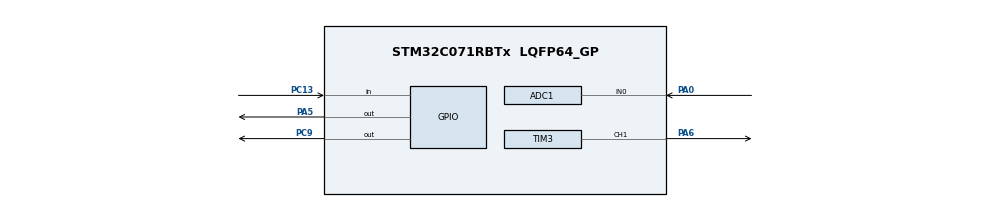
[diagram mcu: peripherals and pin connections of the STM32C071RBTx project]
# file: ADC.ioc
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ADC1.NbrOfConversionFlag=0
ADC1.SelectedChannel=ADC_CHANNEL_0
ADC1.master=1
Mcu.Family=STM32C0
Mcu.Name=STM32C071RBTx
Mcu.Package=LQFP64_GP
NUCLEO-C071RB.BUTTON=1
NUCLEO-C071RB.LD1=true
NUCLEO-C071RB.LD2=true
NUCLEO-C071RB.VCP=true
NVIC.EXTI4_15_IRQn=true\:0\:0\:false\:false\:true\:false\:true\:true
PA0.Mode=IN0
PA0.Signal=ADC1_IN0
PA2.Signal=USART2_TX
PA3.Signal=USART2_RX
PA5.Signal=GPIO_Output
PA6.Signal=S_TIM3_CH1
PC13.Signal=GPIO_Input
PC9.Signal=GPIO_Output
ProjectManager.HeapSize=0x200
ProjectManager.StackSize=0x400
ProjectManager.TargetToolchain=STM32CubeIDE
RCC.ADCFreq_Value=12000000
RCC.AHBFreq_Value=12000000
RCC.CortexFreq_Value=12000000
RCC.EXTERNAL_CLOCK_VALUE=12288000
RCC.HCLKFreq_Value=12000000
RCC.HSE_VALUE=8000000
RCC.HSI48_VALUE=48000000
RCC.HSI_VALUE=48000000
RCC.LSE_VALUE=32768
RCC.SYSCLKFreq_VALUE=12000000
SH.S_TIM3_CH1.0=TIM3_CH1,PWM Generation1 CH1
TIM3.Channel-PWM\ Generation1\ CH1=TIM_CHANNEL_1
TIM3.Period=999
TIM3.Prescaler=11
VP_NUCLEO-C071RB_VS_BSP_COMMON.Mode=COMMON
VP_TIM3_VS_ClockSourceINT.Mode=Internal
board=NUCLEO-C071RB

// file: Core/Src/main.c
/* USER CODE BEGIN Header */
/**
  ******************************************************************************
  * @file           : main.c
  * @brief          : Main program body
  ******************************************************************************
  * @attention
  *
  * Copyright (c) 2026 STMicroelectronics.
  * All rights reserved.
  *
  * This software is licensed under terms that can be found in the LICENSE file
  * in the root directory of this software component.
  * If no LICENSE file comes with this software, it is provided AS-IS.
  *
  ******************************************************************************
  */
/* USER CODE END Header */
#include "main.h"

/* USER CODE BEGIN Includes */
#include <stdio.h>
/* USER CODE END Includes */

COM_InitTypeDef BspCOMInit;
ADC_HandleTypeDef hadc1;

TIM_HandleTypeDef htim3;

/* USER CODE BEGIN PV */
uint32_t adc_value = 0;
uint32_t pwm_value = 0;
/* USER CODE END PV */

void SystemClock_Config(void);
static void MX_GPIO_Init(void);
static void MX_ADC1_Init(void);
static void MX_TIM3_Init(void);

int main(void)
{

  /* MCU Configuration--------------------------------------------------------*/

  /* Reset of all peripherals, Initializes the Flash interface and the Systick. */
  HAL_Init();

  /* Configure the system clock */
  SystemClock_Config();

  /* Initialize all configured peripherals */
  MX_GPIO_Init();
  MX_ADC1_Init();
  MX_TIM3_Init();

  /* Initialize leds */
  BSP_LED_Init(LED_GREEN);
  BSP_LED_Init(LED_BLUE);

  /* Initialize USER push-button, will be used to trigger an interrupt each time it's pressed.*/
  BSP_PB_Init(BUTTON_USER, BUTTON_MODE_EXTI);

  /* Initialize COM1 port (115200, 8 bits (7-bit data + 1 stop bit), no parity */
  BspCOMInit.BaudRate   = 115200;
  BspCOMInit.WordLength = COM_WORDLENGTH_8B;
  BspCOMInit.StopBits   = COM_STOPBITS_1;
  BspCOMInit.Parity     = COM_PARITY_NONE;
  BspCOMInit.HwFlowCtl  = COM_HWCONTROL_NONE;
  if (BSP_COM_Init(COM1, &BspCOMInit) != BSP_ERROR_NONE)
  {
    Error_Handler();
  }

  HAL_TIM_PWM_Start(&htim3, TIM_CHANNEL_1);
  printf("ADC potentiometer project started\r\n");

  /* Infinite loop */
  /* USER CODE BEGIN WHILE */
  while (1)
  {
	  /*
	     * Start ADC conversion
	     */
	    HAL_ADC_Start(&hadc1);

	    /*
	     * Wait for ADC conversion complete
	     */
	    if (HAL_ADC_PollForConversion(&hadc1, 10) == HAL_OK)
	    {
	        /*
	         * Read ADC value: 0 to 4095 for 12-bit ADC
	         */
	        adc_value = HAL_ADC_GetValue(&hadc1);

	        /*
	         * Convert ADC value to PWM duty.
	         * ADC range: 0 to 4095
	         * PWM range: 0 to 999
	         */
	        pwm_value = (adc_value * 999) / 4095;

	        /*
	         * Update PWM duty cycle
	         */
	        __HAL_TIM_SET_COMPARE(&htim3, TIM_CHANNEL_1, pwm_value);
	    }

	    HAL_ADC_Stop(&hadc1);

	    HAL_Delay(10);
    /* USER CODE END WHILE */

  }
}

void SystemClock_Config(void)
{
  RCC_OscInitTypeDef RCC_OscInitStruct = {0};
  RCC_ClkInitTypeDef RCC_ClkInitStruct = {0};

  __HAL_FLASH_SET_LATENCY(FLASH_LATENCY_0);

  /** Initializes the RCC Oscillators according to the specified parameters
  * in the RCC_OscInitTypeDef structure.
  */
  RCC_OscInitStruct.OscillatorType = RCC_OSCILLATORTYPE_HSI;
  RCC_OscInitStruct.HSIState = RCC_HSI_ON;
  RCC_OscInitStruct.HSIDiv = RCC_HSI_DIV4;
  RCC_OscInitStruct.HSICalibrationValue = RCC_HSICALIBRATION_DEFAULT;
  if (HAL_RCC_OscConfig(&RCC_OscInitStruct) != HAL_OK)
  {
    Error_Handler();
  }

  /** Initializes the CPU, AHB and APB buses clocks
  */
  RCC_ClkInitStruct.ClockType = RCC_CLOCKTYPE_HCLK|RCC_CLOCKTYPE_SYSCLK
                              |RCC_CLOCKTYPE_PCLK1;
  RCC_ClkInitStruct.SYSCLKSource = RCC_SYSCLKSOURCE_HSI;
  RCC_ClkInitStruct.SYSCLKDivider = RCC_SYSCLK_DIV1;
  RCC_ClkInitStruct.AHBCLKDivider = RCC_HCLK_DIV1;
  RCC_ClkInitStruct.APB1CLKDivider = RCC_APB1_DIV1;

  if (HAL_RCC_ClockConfig(&RCC_ClkInitStruct, FLASH_LATENCY_0) != HAL_OK)
  {
    Error_Handler();
  }
}

static void MX_ADC1_Init(void)
{

  ADC_ChannelConfTypeDef sConfig = {0};

  /** Configure the global features of the ADC (Clock, Resolution, Data Alignment and number of conversion)
  */
  hadc1.Instance = ADC1;
  hadc1.Init.ClockPrescaler = ADC_CLOCK_SYNC_PCLK_DIV1;
  hadc1.Init.Resolution = ADC_RESOLUTION_12B;
  hadc1.Init.DataAlign = ADC_DATAALIGN_RIGHT;
  hadc1.Init.ScanConvMode = ADC_SCAN_SEQ_FIXED;
  hadc1.Init.EOCSelection = ADC_EOC_SINGLE_CONV;
  hadc1.Init.LowPowerAutoWait = DISABLE;
  hadc1.Init.LowPowerAutoPowerOff = DISABLE;
  hadc1.Init.ContinuousConvMode = DISABLE;
  hadc1.Init.NbrOfConversion = 1;
  hadc1.Init.DiscontinuousConvMode = DISABLE;
  hadc1.Init.ExternalTrigConv = ADC_SOFTWARE_START;
  hadc1.Init.ExternalTrigConvEdge = ADC_EXTERNALTRIGCONVEDGE_NONE;
  hadc1.Init.DMAContinuousRequests = DISABLE;
  hadc1.Init.Overrun = ADC_OVR_DATA_PRESERVED;
  hadc1.Init.SamplingTimeCommon1 = ADC_SAMPLETIME_1CYCLE_5;
  hadc1.Init.OversamplingMode = DISABLE;
  hadc1.Init.TriggerFrequencyMode = ADC_TRIGGER_FREQ_HIGH;
  if (HAL_ADC_Init(&hadc1) != HAL_OK)
  {
    Error_Handler();
  }

  /** Configure Regular Channel
  */
  sConfig.Channel = ADC_CHANNEL_0;
  sConfig.Rank = ADC_RANK_CHANNEL_NUMBER;
  if (HAL_ADC_ConfigChannel(&hadc1, &sConfig) != HAL_OK)
  {
    Error_Handler();
  }

}

static void MX_TIM3_Init(void)
{

  TIM_ClockConfigTypeDef sClockSourceConfig = {0};
  TIM_MasterConfigTypeDef sMasterConfig = {0};
  TIM_OC_InitTypeDef sConfigOC = {0};

  htim3.Instance = TIM3;
  htim3.Init.Prescaler = 11;
  htim3.Init.CounterMode = TIM_COUNTERMODE_UP;
  htim3.Init.Period = 999;
  htim3.Init.ClockDivision = TIM_CLOCKDIVISION_DIV1;
  htim3.Init.AutoReloadPreload = TIM_AUTORELOAD_PRELOAD_DISABLE;
  if (HAL_TIM_Base_Init(&htim3) != HAL_OK)
  {
    Error_Handler();
  }
  sClockSourceConfig.ClockSource = TIM_CLOCKSOURCE_INTERNAL;
  if (HAL_TIM_ConfigClockSource(&htim3, &sClockSourceConfig) != HAL_OK)
  {
    Error_Handler();
  }
  if (HAL_TIM_PWM_Init(&htim3) != HAL_OK)
  {
    Error_Handler();
  }
  sMasterConfig.MasterOutputTrigger = TIM_TRGO_RESET;
  sMasterConfig.MasterSlaveMode = TIM_MASTERSLAVEMODE_DISABLE;
  if (HAL_TIMEx_MasterConfigSynchronization(&htim3, &sMasterConfig) != HAL_OK)
  {
    Error_Handler();
  }
  sConfigOC.OCMode = TIM_OCMODE_PWM1;
  sConfigOC.Pulse = 0;
  sConfigOC.OCPolarity = TIM_OCPOLARITY_HIGH;
  sConfigOC.OCFastMode = TIM_OCFAST_DISABLE;
  if (HAL_TIM_PWM_ConfigChannel(&htim3, &sConfigOC, TIM_CHANNEL_1) != HAL_OK)
  {
    Error_Handler();
  }
  HAL_TIM_MspPostInit(&htim3);

}

static void MX_GPIO_Init(void)
{

  /* GPIO Ports Clock Enable */
  __HAL_RCC_GPIOA_CLK_ENABLE();

}

void Error_Handler(void)
{
  __disable_irq();
  while (1)
  {
  }
}
